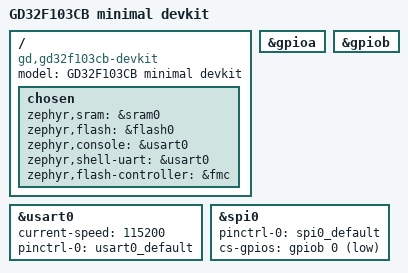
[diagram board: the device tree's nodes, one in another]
/*
 * Copyright (c) 2026
 * SPDX-License-Identifier: Apache-2.0
 */

/dts-v1/;

#include <gd/gd32f10x/gd32f103cbt6.dtsi>
#include "gd32f103cb_devkit-pinctrl.dtsi"

/ {
	model = "GD32F103CB minimal devkit";
	compatible = "gd,gd32f103cb-devkit";

	chosen {
		zephyr,sram = &sram0;
		zephyr,flash = &flash0;
		zephyr,console = &usart0;
		zephyr,shell-uart = &usart0;
		zephyr,flash-controller = &fmc;
	};
};

&gpioa {
	status = "okay";
};

&gpiob {
	status = "okay";
};

&usart0 {
	status = "okay";
	current-speed = <115200>;
	pinctrl-0 = <&usart0_default>;
	pinctrl-names = "default";
};

&spi0 {
	status = "okay";
	pinctrl-0 = <&spi0_default>;
	pinctrl-names = "default";
	cs-gpios = <&gpiob 0 GPIO_ACTIVE_LOW>;
};

